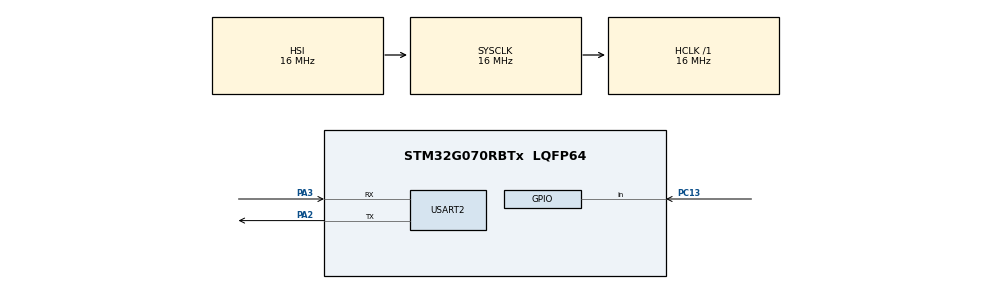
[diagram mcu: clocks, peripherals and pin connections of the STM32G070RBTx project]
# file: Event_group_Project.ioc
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Mcu.Family=STM32G0
Mcu.Name=STM32G070RBTx
Mcu.Package=LQFP64
NVIC.TIM3_IRQn=true\:3\:0\:false\:false\:true\:false\:true\:true
NVIC.TimeBase=TIM3_IRQn
NVIC.TimeBaseIP=TIM3
PA13.Mode=Serial_Wire
PA13.Signal=SYS_SWDIO
PA14-BOOT0.Mode=Serial_Wire
PA14-BOOT0.Signal=SYS_SWCLK
PA2.Mode=Asynchronous
PA2.Signal=USART2_TX
PA3.Mode=Asynchronous
PA3.Signal=USART2_RX
PC13.Signal=GPIO_Input
PC14-OSC32_IN\ (PC14).Mode=LSE-External-Oscillator
PC14-OSC32_IN\ (PC14).Signal=RCC_OSC32_IN
PC15-OSC32_OUT\ (PC15).Mode=LSE-External-Oscillator
PC15-OSC32_OUT\ (PC15).Signal=RCC_OSC32_OUT
PF0-OSC_IN\ (PF0).Mode=HSE-External-Clock-Source
PF0-OSC_IN\ (PF0).Signal=RCC_OSC_IN
ProjectManager.HeapSize=0x200
ProjectManager.StackSize=0x400
ProjectManager.TargetToolchain=STM32CubeIDE
RCC.AHBFreq_Value=16000000
RCC.CortexFreq_Value=16000000
RCC.EXTERNAL_CLOCK_VALUE=12288000
RCC.HCLKFreq_Value=16000000
RCC.HSE_VALUE=8000000
RCC.HSI_VALUE=16000000
RCC.SYSCLKFreq_VALUE=16000000
RCC.VCOOutputFreq_Value=128000000
USART2.VirtualMode-Asynchronous=VM_ASYNC
VP_SYS_VS_tim3.Mode=TIM3
board=NUCLEO-G070RB

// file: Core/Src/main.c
/* USER CODE BEGIN Header */
/**
  ******************************************************************************
  * @file           : main.c
  * @brief          : Main program body
  ******************************************************************************
  * @attention
  *
  * Copyright (c) 2023 STMicroelectronics.
  * All rights reserved.
  *
  * This software is licensed under terms that can be found in the LICENSE file
  * in the root directory of this software component.
  * If no LICENSE file comes with this software, it is provided AS-IS.
  *
  ******************************************************************************
  */
/* USER CODE END Header */
#include "main.h"

/* USER CODE BEGIN Includes */
#include "FreeRTOS.h"
#include "task.h"
#include "event_groups.h"

/* USER CODE END Includes */

/* USER CODE BEGIN PM */
#define TASK1_BIT   (1UL << 0UL)
#define TASK2_BIT   (1UL << 1UL)
#define TASK3_BIT   (1UL << 2UL)

/* USER CODE END PM */

UART_HandleTypeDef huart2;

/* USER CODE BEGIN PV */
EventGroupHandle_t EventGroup;
const TickType_t Delay = pdMS_TO_TICKS(500);

/* USER CODE END PV */

void SystemClock_Config(void);
static void MX_GPIO_Init(void);
static void MX_USART2_UART_Init(void);
/* USER CODE BEGIN PFP */
void Input1 (void *p);
void Input2 (void *p);
void Input3 (void *p);
void Output (void *p);

/* USER CODE END PFP */

/* USER CODE BEGIN 0 */
void Input1 (void *p)
{
	while(1)
	{
		xEventGroupSetBits(EventGroup, TASK1_BIT);
		vTaskDelay(Delay);
	}
}

void Input2 (void *p)
{
	while(1)
	{
		xEventGroupSetBits(EventGroup, TASK2_BIT);
		vTaskDelay(Delay);
	}
}

void Input3 (void *p)
{
	while(1)
	{
		xEventGroupSetBits(EventGroup, TASK3_BIT);
		vTaskDelay(Delay);
	}
}

void Output (void *p)
{
	const EventBits_t xBitsToWaitFor = (TASK1_BIT | TASK2_BIT | TASK3_BIT );
	EventBits_t xEventGroupValue;
	while(1)
	{
		xEventGroupValue = xEventGroupWaitBits(EventGroup, xBitsToWaitFor, pdTRUE, pdTRUE, portMAX_DELAY);

		if((xEventGroupValue & TASK1_BIT) != 0)
		{
			HAL_UART_Transmit (&huart2, (uint8_t *) "Task1 evnt running \r\n\n", 24, 100);

		}
		if((xEventGroupValue & TASK2_BIT) != 0)
				{
					HAL_UART_Transmit (&huart2, (uint8_t *) "Task2 evnt running \r\n\n", 24, 100);

				}
		if(HAL_GPIO_ReadPin(GPIOC,GPIO_PIN_13) == 0)
		{
		if((xEventGroupValue & TASK3_BIT) != 0)
				{
					HAL_UART_Transmit (&huart2, (uint8_t *) "Task3 evnt running \r\n\n", 24, 100);

				}
		}
		else{
			HAL_UART_Transmit (&huart2, (uint8_t *) "Task3 evnt not running \r\n\n", 27, 100);
		}
		/*xEventGroupSetBits(EventGroup, TASK1_BIT);
		vTaskDelay(Delay);*/
	}
}

/* USER CODE END 0 */

int main(void)
{

  /* MCU Configuration--------------------------------------------------------*/

  /* Reset of all peripherals, Initializes the Flash interface and the Systick. */
  HAL_Init();

  /* Configure the system clock */
  SystemClock_Config();

  /* Initialize all configured peripherals */
  MX_GPIO_Init();
  MX_USART2_UART_Init();
  /* USER CODE BEGIN 2 */
  EventGroup = xEventGroupCreate();

    xTaskCreate(Input1, "input1", 100, NULL, 1, NULL);
    xTaskCreate(Input2, "input2", 100, NULL, 1, NULL);
    xTaskCreate(Input3, "input3", 100, NULL, 1, NULL);
    xTaskCreate(Output, "output", 100, NULL, 1, NULL);

    vTaskStartScheduler();

  /* USER CODE END 2 */

  /* Infinite loop */
  while (1)
  {

  }
}

void SystemClock_Config(void)
{
  RCC_OscInitTypeDef RCC_OscInitStruct = {0};
  RCC_ClkInitTypeDef RCC_ClkInitStruct = {0};

  /** Configure the main internal regulator output voltage
  */
  HAL_PWREx_ControlVoltageScaling(PWR_REGULATOR_VOLTAGE_SCALE1);

  /** Initializes the RCC Oscillators according to the specified parameters
  * in the RCC_OscInitTypeDef structure.
  */
  RCC_OscInitStruct.OscillatorType = RCC_OSCILLATORTYPE_HSI;
  RCC_OscInitStruct.HSIState = RCC_HSI_ON;
  RCC_OscInitStruct.HSIDiv = RCC_HSI_DIV1;
  RCC_OscInitStruct.HSICalibrationValue = RCC_HSICALIBRATION_DEFAULT;
  RCC_OscInitStruct.PLL.PLLState = RCC_PLL_NONE;
  if (HAL_RCC_OscConfig(&RCC_OscInitStruct) != HAL_OK)
  {
    Error_Handler();
  }

  /** Initializes the CPU, AHB and APB buses clocks
  */
  RCC_ClkInitStruct.ClockType = RCC_CLOCKTYPE_HCLK|RCC_CLOCKTYPE_SYSCLK
                              |RCC_CLOCKTYPE_PCLK1;
  RCC_ClkInitStruct.SYSCLKSource = RCC_SYSCLKSOURCE_HSI;
  RCC_ClkInitStruct.AHBCLKDivider = RCC_SYSCLK_DIV1;
  RCC_ClkInitStruct.APB1CLKDivider = RCC_HCLK_DIV1;

  if (HAL_RCC_ClockConfig(&RCC_ClkInitStruct, FLASH_LATENCY_0) != HAL_OK)
  {
    Error_Handler();
  }
}

static void MX_USART2_UART_Init(void)
{

  huart2.Instance = USART2;
  huart2.Init.BaudRate = 115200;
  huart2.Init.WordLength = UART_WORDLENGTH_8B;
  huart2.Init.StopBits = UART_STOPBITS_1;
  huart2.Init.Parity = UART_PARITY_NONE;
  huart2.Init.Mode = UART_MODE_TX_RX;
  huart2.Init.HwFlowCtl = UART_HWCONTROL_NONE;
  huart2.Init.OverSampling = UART_OVERSAMPLING_16;
  huart2.Init.OneBitSampling = UART_ONE_BIT_SAMPLE_DISABLE;
  huart2.Init.ClockPrescaler = UART_PRESCALER_DIV1;
  huart2.AdvancedInit.AdvFeatureInit = UART_ADVFEATURE_NO_INIT;
  if (HAL_UART_Init(&huart2) != HAL_OK)
  {
    Error_Handler();
  }
  if (HAL_UARTEx_SetTxFifoThreshold(&huart2, UART_TXFIFO_THRESHOLD_1_8) != HAL_OK)
  {
    Error_Handler();
  }
  if (HAL_UARTEx_SetRxFifoThreshold(&huart2, UART_RXFIFO_THRESHOLD_1_8) != HAL_OK)
  {
    Error_Handler();
  }
  if (HAL_UARTEx_DisableFifoMode(&huart2) != HAL_OK)
  {
    Error_Handler();
  }

}

static void MX_GPIO_Init(void)
{
  GPIO_InitTypeDef GPIO_InitStruct = {0};

  /* GPIO Ports Clock Enable */
  __HAL_RCC_GPIOC_CLK_ENABLE();
  __HAL_RCC_GPIOF_CLK_ENABLE();
  __HAL_RCC_GPIOA_CLK_ENABLE();

  /*Configure GPIO pin : PC13 */
  GPIO_InitStruct.Pin = GPIO_PIN_13;
  GPIO_InitStruct.Mode = GPIO_MODE_INPUT;
  GPIO_InitStruct.Pull = GPIO_NOPULL;
  HAL_GPIO_Init(GPIOC, &GPIO_InitStruct);

}

void HAL_TIM_PeriodElapsedCallback(TIM_HandleTypeDef *htim)
{
  if (htim->Instance == TIM3) {
    HAL_IncTick();
  }
}

void Error_Handler(void)
{
  __disable_irq();
  while (1)
  {
  }
}
